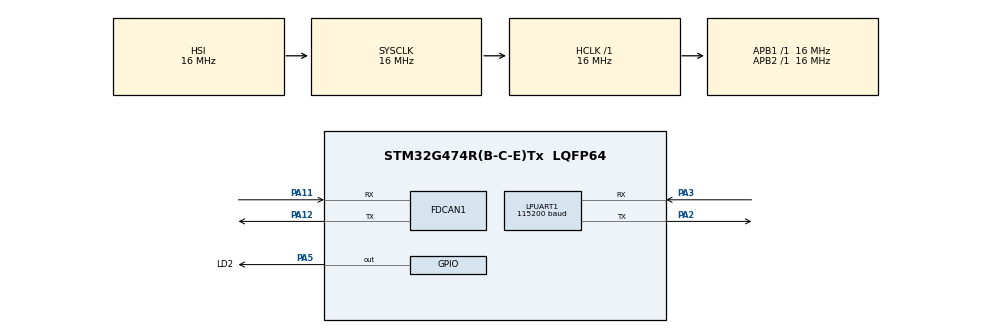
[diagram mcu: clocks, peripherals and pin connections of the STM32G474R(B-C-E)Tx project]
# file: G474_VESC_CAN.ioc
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FDCAN1.AutoRetransmission=DISABLE
FDCAN1.CalculateBaudRateNominal=250000
FDCAN1.CalculateTimeBitNominal=4000
FDCAN1.CalculateTimeQuantumNominal=125.0
FDCAN1.ExtFiltersNbr=1
FDCAN1.NominalPrescaler=2
FDCAN1.NominalSyncJumpWidth=4
FDCAN1.NominalTimeSeg1=25
FDCAN1.NominalTimeSeg2=6
FDCAN1.StdFiltersNbr=0
LPUART1.BaudRate=115200
Mcu.Family=STM32G4
Mcu.Name=STM32G474R(B-C-E)Tx
Mcu.Package=LQFP64
NVIC.LPUART1_IRQn=true\:1\:0\:false\:false\:true\:true\:true\:true
NVIC.PriorityGroup=NVIC_PRIORITYGROUP_4
PA11.Mode=FDCAN_Activate
PA11.Signal=FDCAN1_RX
PA12.Mode=FDCAN_Activate
PA12.Signal=FDCAN1_TX
PA13.Mode=Serial_Wire
PA13.Signal=SYS_JTMS-SWDIO
PA14.Mode=Serial_Wire
PA14.Signal=SYS_JTCK-SWCLK
PA2.Mode=Asynchronous
PA2.Signal=LPUART1_TX
PA3.Mode=Asynchronous
PA3.Signal=LPUART1_RX
PA5.GPIO_Label=LD2
PA5.Signal=GPIO_Output
ProjectManager.HeapSize=0x200
ProjectManager.StackSize=0x400
ProjectManager.TargetToolchain=STM32CubeIDE
RCC.AHBFreq_Value=16000000
RCC.APB1Freq_Value=16000000
RCC.APB1TimFreq_Value=16000000
RCC.APB2Freq_Value=16000000
RCC.APB2TimFreq_Value=16000000
RCC.CortexFreq_Value=16000000
RCC.EXTERNAL_CLOCK_VALUE=12288000
RCC.HCLKFreq_Value=16000000
RCC.HSE_VALUE=8000000
RCC.HSI48_VALUE=48000000
RCC.HSI_VALUE=16000000
RCC.LSE_VALUE=32768
RCC.SYSCLKFreq_VALUE=16000000
RCC.USBFreq_Value=64000000
RCC.VCOOutputFreq_Value=128000000
VP_SYS_VS_DBSignals.Mode=DisableDeadBatterySignals
board=custom

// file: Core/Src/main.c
/* USER CODE BEGIN Header */
/**
  ******************************************************************************
  * @file           : main.c
  * @brief          : Main program body
  ******************************************************************************
  * @attention
  *
  * Copyright (c) 2026 STMicroelectronics.
  * All rights reserved.
  *
  * This software is licensed under terms that can be found in the LICENSE file
  * in the root directory of this software component.
  * If no LICENSE file comes with this software, it is provided AS-IS.
  *
  ******************************************************************************
  */
/* USER CODE END Header */
#include "main.h"

/* USER CODE BEGIN Includes */
#include "bldc_app.h"
/* USER CODE END Includes */

FDCAN_HandleTypeDef hfdcan1;

UART_HandleTypeDef hlpuart1;

void SystemClock_Config(void);
static void MX_GPIO_Init(void);
static void MX_FDCAN1_Init(void);
static void MX_LPUART1_UART_Init(void);

int main(void)
{

  /* MCU Configuration--------------------------------------------------------*/

  /* Reset of all peripherals, Initializes the Flash interface and the Systick. */
  HAL_Init();

  /* Configure the system clock */
  SystemClock_Config();

  /* Initialize all configured peripherals */
  MX_GPIO_Init();
  MX_FDCAN1_Init();
  MX_LPUART1_UART_Init();
  /* USER CODE BEGIN 2 */
  BldcApp_Init(&hfdcan1, &hlpuart1);
  /* USER CODE END 2 */

  /* Infinite loop */
  while (1)
  {

    /* USER CODE BEGIN 3 */
    BldcApp_Poll();
    HAL_Delay(1);
  }
  /* USER CODE END 3 */
}

void SystemClock_Config(void)
{
  RCC_OscInitTypeDef RCC_OscInitStruct = {0};
  RCC_ClkInitTypeDef RCC_ClkInitStruct = {0};

  /** Configure the main internal regulator output voltage
  */
  HAL_PWREx_ControlVoltageScaling(PWR_REGULATOR_VOLTAGE_SCALE1);

  /** Initializes the RCC Oscillators according to the specified parameters
  * in the RCC_OscInitTypeDef structure.
  */
  RCC_OscInitStruct.OscillatorType = RCC_OSCILLATORTYPE_HSI;
  RCC_OscInitStruct.HSIState = RCC_HSI_ON;
  RCC_OscInitStruct.HSICalibrationValue = RCC_HSICALIBRATION_DEFAULT;
  RCC_OscInitStruct.PLL.PLLState = RCC_PLL_NONE;
  if (HAL_RCC_OscConfig(&RCC_OscInitStruct) != HAL_OK)
  {
    Error_Handler();
  }

  /** Initializes the CPU, AHB and APB buses clocks
  */
  RCC_ClkInitStruct.ClockType = RCC_CLOCKTYPE_HCLK|RCC_CLOCKTYPE_SYSCLK
                              |RCC_CLOCKTYPE_PCLK1|RCC_CLOCKTYPE_PCLK2;
  RCC_ClkInitStruct.SYSCLKSource = RCC_SYSCLKSOURCE_HSI;
  RCC_ClkInitStruct.AHBCLKDivider = RCC_SYSCLK_DIV1;
  RCC_ClkInitStruct.APB1CLKDivider = RCC_HCLK_DIV1;
  RCC_ClkInitStruct.APB2CLKDivider = RCC_HCLK_DIV1;

  if (HAL_RCC_ClockConfig(&RCC_ClkInitStruct, FLASH_LATENCY_0) != HAL_OK)
  {
    Error_Handler();
  }
}

static void MX_FDCAN1_Init(void)
{

  hfdcan1.Instance = FDCAN1;
  hfdcan1.Init.ClockDivider = FDCAN_CLOCK_DIV1;
  hfdcan1.Init.FrameFormat = FDCAN_FRAME_CLASSIC;
  hfdcan1.Init.Mode = FDCAN_MODE_NORMAL;
  hfdcan1.Init.AutoRetransmission = DISABLE;
  hfdcan1.Init.TransmitPause = DISABLE;
  hfdcan1.Init.ProtocolException = DISABLE;
  hfdcan1.Init.NominalPrescaler = 2;
  hfdcan1.Init.NominalSyncJumpWidth = 4;
  hfdcan1.Init.NominalTimeSeg1 = 25;
  hfdcan1.Init.NominalTimeSeg2 = 6;
  hfdcan1.Init.DataPrescaler = 1;
  hfdcan1.Init.DataSyncJumpWidth = 1;
  hfdcan1.Init.DataTimeSeg1 = 1;
  hfdcan1.Init.DataTimeSeg2 = 1;
  hfdcan1.Init.StdFiltersNbr = 0;
  hfdcan1.Init.ExtFiltersNbr = 1;
  hfdcan1.Init.TxFifoQueueMode = FDCAN_TX_FIFO_OPERATION;
  if (HAL_FDCAN_Init(&hfdcan1) != HAL_OK)
  {
    Error_Handler();
  }

}

static void MX_LPUART1_UART_Init(void)
{

  hlpuart1.Instance = LPUART1;
  hlpuart1.Init.BaudRate = 115200;
  hlpuart1.Init.WordLength = UART_WORDLENGTH_8B;
  hlpuart1.Init.StopBits = UART_STOPBITS_1;
  hlpuart1.Init.Parity = UART_PARITY_NONE;
  hlpuart1.Init.Mode = UART_MODE_TX_RX;
  hlpuart1.Init.HwFlowCtl = UART_HWCONTROL_NONE;
  hlpuart1.Init.OneBitSampling = UART_ONE_BIT_SAMPLE_DISABLE;
  hlpuart1.Init.ClockPrescaler = UART_PRESCALER_DIV1;
  hlpuart1.AdvancedInit.AdvFeatureInit = UART_ADVFEATURE_NO_INIT;
  if (HAL_UART_Init(&hlpuart1) != HAL_OK)
  {
    Error_Handler();
  }
  if (HAL_UARTEx_SetTxFifoThreshold(&hlpuart1, UART_TXFIFO_THRESHOLD_1_8) != HAL_OK)
  {
    Error_Handler();
  }
  if (HAL_UARTEx_SetRxFifoThreshold(&hlpuart1, UART_RXFIFO_THRESHOLD_1_8) != HAL_OK)
  {
    Error_Handler();
  }
  if (HAL_UARTEx_DisableFifoMode(&hlpuart1) != HAL_OK)
  {
    Error_Handler();
  }

}

static void MX_GPIO_Init(void)
{
  GPIO_InitTypeDef GPIO_InitStruct = {0};

  /* GPIO Ports Clock Enable */
  __HAL_RCC_GPIOA_CLK_ENABLE();

  /*Configure GPIO pin Output Level */
  HAL_GPIO_WritePin(LD2_GPIO_Port, LD2_Pin, GPIO_PIN_RESET);

  /*Configure GPIO pin : LD2_Pin */
  GPIO_InitStruct.Pin = LD2_Pin;
  GPIO_InitStruct.Mode = GPIO_MODE_OUTPUT_PP;
  GPIO_InitStruct.Pull = GPIO_NOPULL;
  GPIO_InitStruct.Speed = GPIO_SPEED_FREQ_LOW;
  HAL_GPIO_Init(LD2_GPIO_Port, &GPIO_InitStruct);

}

void Error_Handler(void)
{
  __disable_irq();
  while (1)
  {
  }
}
